# AST1060 register map
File version: 1.0
CPU: CM4 r0p1, little endian, MPU, FPU, 4 interrupt priority bits, 256 interrupts
Registers are 32-bit, read-write, reset 0x0 unless marked. A register's access mark holds for its fields unless they carry their own. Offsets are from the block's base; [hi:lo] are bit positions; {n}, {i} and the like mark numbered series; 'fields as' and 'values as' point back to an identical list.

## wdt
Base 0x7E785000
Same registers: wdt1 0x7E785080, wdt2 0x7E785100, wdt3 0x7E785180
0x00 WDT000 reset 0x14FB180 — WDTn Counter Status Register
  [31:0] CounterSts ro — Counter status
0x04 WDT004 reset 0x14FB180 — WDTn Counter Reload Value Register
  [31:0] CounterReloadValueReg — Counter reload value register
0x08 WDT008 — WDTn Counter Restart Register
  [15:0] RestartReg — Restart register
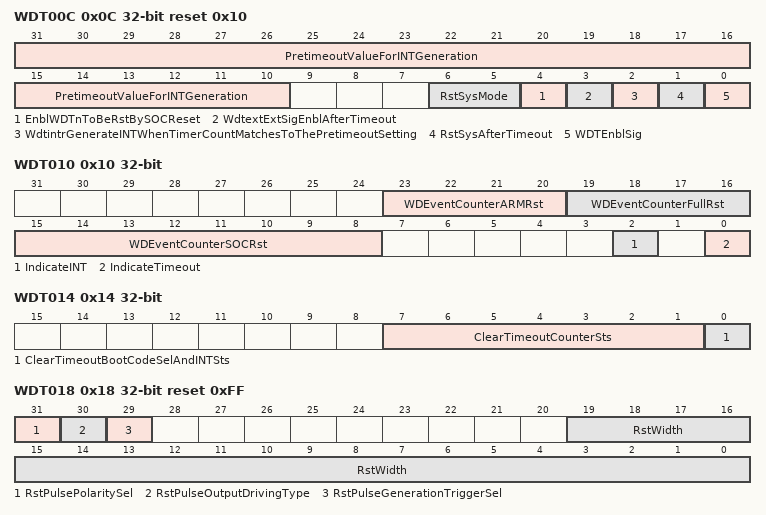
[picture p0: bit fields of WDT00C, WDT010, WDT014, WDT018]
0x0C WDT00C reset 0x10 — WDTn Control Register
  [31:10] PretimeoutValueForINTGeneration — Pre-timeout value for interrupt generation
  [6:5] RstSysMode — Reset system mode
    0=SOC_System_Ewvergated_By_Reset_Mask_Registers; 1=Full_Chip; 0b1x=CPUFMC_Only_Just_Reboot_Firmware_No_Any_Other_IPs_Will_Be_Reset
  [4] EnblWDTnToBeRstBySOCReset — Enable WDT(n) to be reset by SOC reset
    0=WDTn_Can_Not_Be_Reset_By_SOC_Reset_Only_SRST_Or_Full_Chip_Reset_Can_Reset_It; 1=WDTn_Can_Be_Reset_By_SOC_Reset
  [3] WdtextExtSigEnblAfterTimeout — wdt_ext: External signal enable after timeout
    0=Disable; 1=Enable
  [2] WdtintrGenerateINTWhenTimerCountMatchesToThePretimeoutSetting — wdt_intr: Generate interrupt when timer count matches to the pre-timeout setting
    0=Disable; 1=Enable
  [1] RstSysAfterTimeout — Reset system after timeout
    0=Disable; 1=Enable
  [0] WDTEnblSig — WDT enable signal
    0=Disable; 1=Enable
0x10 WDT010 — WDTn Timeout Status Register
  [23:20] WDEventCounterARMRst ro — Watchdog event counter : ARM reset
  [19:16] WDEventCounterFullRst ro — Watchdog event counter : Full reset
  [15:8] WDEventCounterSOCRst ro — Watchdog event counter : SOC reset
  [2] IndicateINT ro — Indicate interrupt
  [0] IndicateTimeout ro
    0=Timeout_Never_Occur; 1=Timeout_Occur
0x14 WDT014 — WDTn Clear Timeout Status Register
  [7:1] ClearTimeoutCounterSts — Clear timeout counter status
  [0] ClearTimeoutBootCodeSelAndINTSts — Clear timeout, boot code selection and interrupt status
0x18 WDT018 reset 0xFF — WDTn Reset Width Register
  [31] RstPulsePolaritySel — Reset pulse polarity selection
    0=Active_Low_Output; 1=Active_High_Output
  [30] RstPulseOutputDrivingType — Reset pulse output driving type
    0=Opendrain; 1=Pushpull
  [29] RstPulseGenerationTriggerSel — Reset pulse generation trigger selection
    0=Trigger_By_Timeout; 1=Trigger_By_Pretimeout
  [19:0] RstWidth — Reset width
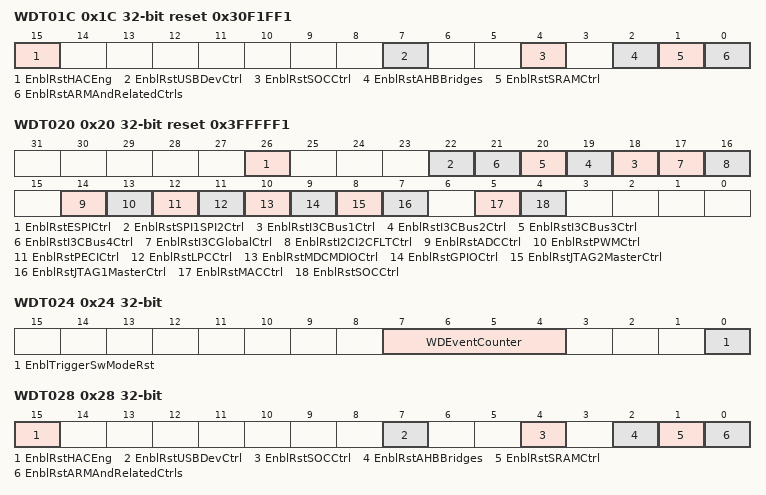
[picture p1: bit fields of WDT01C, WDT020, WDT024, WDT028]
0x1C WDT01C reset 0x30F1FF1 (reset mask 0x8017) — WDTn Reset Mask Register \#1
  [15] EnblRstHACEng — Enable reset HAC engine
  [7] EnblRstUSBDevCtrl — Enable reset USB Dev controller
  [4] EnblRstSOCCtrl — Enable reset SOC controller
  [2] EnblRstAHBBridges — Enable reset AHB bridges
  [1] EnblRstSRAMCtrl — Enable reset SRAM controller
  [0] EnblRstARMAndRelatedCtrls — Enable reset ARM and related controllers
0x20 WDT020 reset 0x3FFFFF1 (reset mask 0x7F4390) — WDTn Reset Mask Register \#2
  [26] EnblRstESPICtrl — Enable reset eSPI controller
  [22] EnblRstSPI1SPI2Ctrl — Enable reset SPI1/SPI2 controller
  [n+17] EnblRstI3CBus{n}Ctrl (n=1..4) — Enable reset I3C bus{n} controller
  [17] EnblRstI3CGlobalCtrl — Enable reset I3C Global controller
  [16] EnblRstI2CI2CFLTCtrl — Enable reset I2C/I2CFLT controller
  [14] EnblRstADCCtrl — Enable reset ADC controller
  [13] EnblRstPWMCtrl — Enable reset PWM controller
  [12] EnblRstPECICtrl — Enable reset PECI controller
  [11] EnblRstLPCCtrl — Enable reset LPC controller
  [10] EnblRstMDCMDIOCtrl — Enable reset MDC/MDIO controller
  [9] EnblRstGPIOCtrl — Enable reset GPIO controller
  [8] EnblRstJTAG2MasterCtrl — Enable reset JTAG #2 master controller
  [7] EnblRstJTAG1MasterCtrl — Enable reset JTAG #1 master controller
  [5] EnblRstMACCtrl — Enable reset MAC controller
  [4] EnblRstSOCCtrl — Enable reset SOC controller
0x24 WDT024 — WDTn Software Mode Reset Control Register
  [7:4] WDEventCounter — Watchdog event counter
  [0] EnblTriggerSwModeRst — Enable trigger software mode reset
0x28 WDT028 (reset mask 0x8017) — WDTn Software Mode Reset Mask Register \#1)
  fields as WDT01C
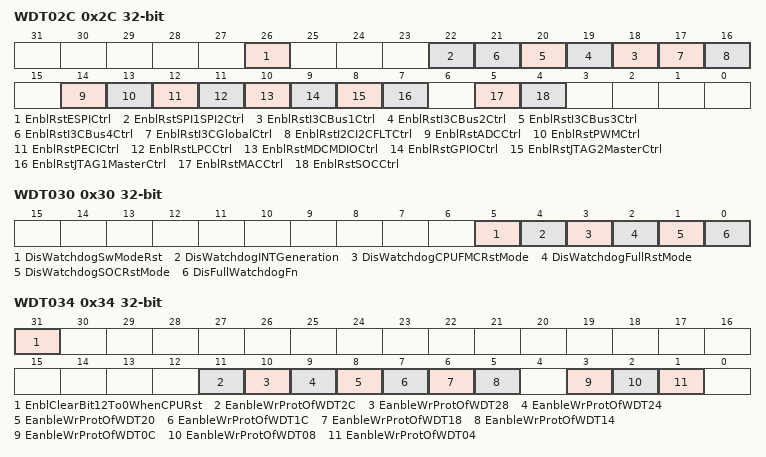
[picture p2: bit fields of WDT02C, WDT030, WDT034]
0x2C WDT02C (reset mask 0x7F4390) — WDTn Software Mode Reset Mask Register \#2
  fields as WDT020
0x30 WDT030 — WDTn Funtion Disable Control Register
  [5] DisWatchdogSwModeRst — Disable watchdog Software mode reset
  [4] DisWatchdogINTGeneration — Disable watchdog interrupt generation
  [3] DisWatchdogCPUFMCRstMode — Disable watchdog CPU/FMC reset mode
  [2] DisWatchdogFullRstMode — Disable watchdog Full reset mode
  [1] DisWatchdogSOCRstMode — Disable watchdog SOC reset mode
  [0] DisFullWatchdogFn — Disable full watchdog function
0x34 WDT034 — WDTn Write Protection Register
  [31] EnblClearBit12To0WhenCPURst — Enable clear bit 12 to 0 when CPU reset
  [11] EanbleWrProtOfWDT2C — Eanble Write Protection of WDT2C
  [10] EanbleWrProtOfWDT28 — Eanble Write Protection of WDT28
  [9] EanbleWrProtOfWDT24 — Eanble Write Protection of WDT24
  [8] EanbleWrProtOfWDT20 — Eanble Write Protection of WDT20
  [7] EanbleWrProtOfWDT1C — Eanble Write Protection of WDT1C
  [6] EanbleWrProtOfWDT18 — Eanble Write Protection of WDT18
  [5] EanbleWrProtOfWDT14 — Eanble Write Protection of WDT14
  [3] EanbleWrProtOfWDT0C — Eanble Write Protection of WDT0C
  [2] EanbleWrProtOfWDT08 — Eanble Write Protection of WDT08
  [1] EanbleWrProtOfWDT04 — Eanble Write Protection of WDT04
0x40 WDT040 — WDTn Reset Mask Write Protection Register \#1
  [31:0] EnblWrProtOfWDT1Cn — Enable Write Protection of WDT1C[n]
0x44 WDT044 — WDTn Reset Mask Write Protection Register \#2
  [31:0] EnblWrProtOfWDT20n — Enable Write Protection of WDT20[n]
0x48 WDT048 — WDTn Software Mode Reset Mask Write Protection Register \#1
  [31:0] EnblWrProtOfWDT28n — Enable Write Protection of WDT28[n]
0x4C WDT04C — WDTn Software Mode Reset Mask Write Protection Register \#2
  [31:0] EnblWrProtOfWDT2Cn — Enable Write Protection of WDT2C[n]
